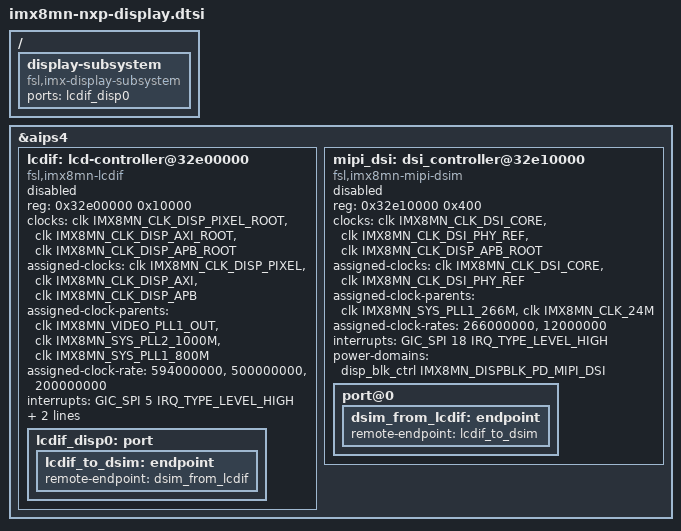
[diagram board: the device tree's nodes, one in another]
// SPDX-License-Identifier: (GPL-2.0+ OR MIT)
/*
 * Copyright 2025 NXP
 */

/delete-node/ &lcdif;
/delete-node/ &mipi_dsi;

/ {
	display-subsystem {
		compatible = "fsl,imx-display-subsystem";
		ports = <&lcdif_disp0>;
	};
};

&aips4 {
	lcdif: lcd-controller@32e00000 {
		compatible = "fsl,imx8mn-lcdif";
		reg = <0x32e00000 0x10000>;
		clocks = <&clk IMX8MN_CLK_DISP_PIXEL_ROOT>,
			 <&clk IMX8MN_CLK_DISP_AXI_ROOT>,
			 <&clk IMX8MN_CLK_DISP_APB_ROOT>;
		clock-names = "pix", "disp-axi", "disp-apb";
		assigned-clocks = <&clk IMX8MN_CLK_DISP_PIXEL>,
				  <&clk IMX8MN_CLK_DISP_AXI>,
				  <&clk IMX8MN_CLK_DISP_APB>;
		assigned-clock-parents = <&clk IMX8MN_VIDEO_PLL1_OUT>,
					 <&clk IMX8MN_SYS_PLL2_1000M>,
					 <&clk IMX8MN_SYS_PLL1_800M>;
		assigned-clock-rate = <594000000>,
				      <500000000>,
				      <200000000>;
		interrupts = <GIC_SPI 5 IRQ_TYPE_LEVEL_HIGH>;
		power-domains = <&disp_blk_ctrl IMX8MN_DISPBLK_PD_LCDIF>;
		status = "disabled";

		lcdif_disp0: port {
			lcdif_to_dsim: endpoint {
				remote-endpoint = <&dsim_from_lcdif>;
			};
		};
	};

	mipi_dsi: dsi_controller@32e10000 {
		#address-cells = <1>;
		#size-cells = <0>;
		compatible = "fsl,imx8mn-mipi-dsim";
		reg = <0x32e10000 0x400>;
		clocks = <&clk IMX8MN_CLK_DSI_CORE>,
			 <&clk IMX8MN_CLK_DSI_PHY_REF>,
			 <&clk IMX8MN_CLK_DISP_APB_ROOT>;
		clock-names = "cfg", "pll-ref", "apb-root";
		assigned-clocks = <&clk IMX8MN_CLK_DSI_CORE>,
				  <&clk IMX8MN_CLK_DSI_PHY_REF>;
		assigned-clock-parents = <&clk IMX8MN_SYS_PLL1_266M>,
					 <&clk IMX8MN_CLK_24M>;
		assigned-clock-rates = <266000000>,
				       <12000000>;
		interrupts = <GIC_SPI 18 IRQ_TYPE_LEVEL_HIGH>;
		power-domains = <&disp_blk_ctrl IMX8MN_DISPBLK_PD_MIPI_DSI>;
		status = "disabled";

		port@0 {
			dsim_from_lcdif: endpoint {
				remote-endpoint = <&lcdif_to_dsim>;
			};
		};
	};
};

